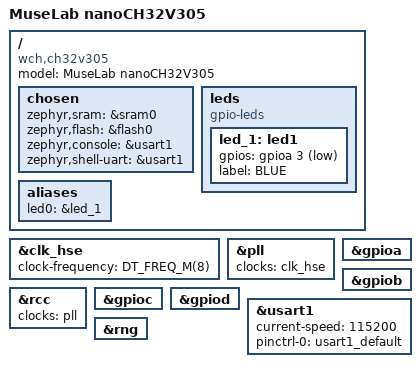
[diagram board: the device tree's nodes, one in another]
/*
 * Copyright (c) 2026 nanoCH32V305 contributors
 * SPDX-License-Identifier: Apache-2.0
 */

/dts-v1/;

#include <wch/ch32v305/ch32v305rb.dtsi>
#include <zephyr/dt-bindings/gpio/gpio.h>
#include "nano_ch32v305-pinctrl.dtsi"

/ {
	model = "MuseLab nanoCH32V305";
	compatible = "wch,ch32v305";

	chosen {
		zephyr,sram = &sram0;
		zephyr,flash = &flash0;
		zephyr,console = &usart1;
		zephyr,shell-uart = &usart1;
	};

	leds {
		compatible = "gpio-leds";

		led_1: led1 {
			gpios = <&gpioa 3 GPIO_ACTIVE_LOW>;
			label = "BLUE";
		};
	};

	aliases {
		led0 = &led_1;
	};
};

&clk_hse {
	status = "okay";
	clock-frequency = <DT_FREQ_M(8)>;
};

&pll {
	clocks = <&clk_hse>;
	status = "okay";
};

&rcc {
	clocks = <&pll>;
};

&gpioa {
	status = "okay";
};

&gpiob {
	status = "okay";
};

&gpioc {
	status = "okay";
};

&gpiod {
	status = "okay";
};

&usart1 {
	status = "okay";
	current-speed = <115200>;
	pinctrl-0 = <&usart1_default>;
	pinctrl-names = "default";
};

&rng {
	status = "okay";
};
